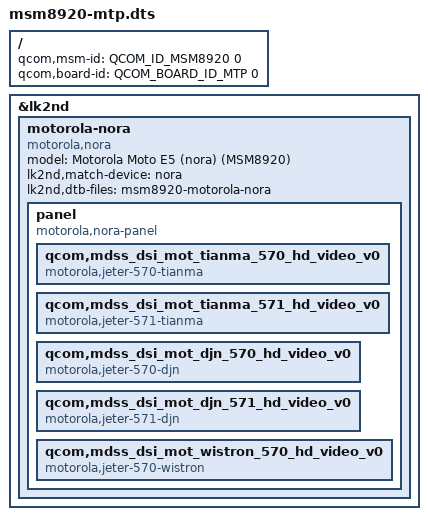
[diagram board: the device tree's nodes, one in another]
// SPDX-License-Identifier: BSD-3-Clause

/dts-v1/;

#include <skeleton64.dtsi>
#include <lk2nd.dtsi>

/ {
	qcom,msm-id = <QCOM_ID_MSM8920 0>;
	qcom,board-id = <QCOM_BOARD_ID_MTP 0>;
};

&lk2nd {
	motorola-nora {
		model = "Motorola Moto E5 (nora) (MSM8920)";
		compatible = "motorola,nora";
		lk2nd,match-device = "nora";

		lk2nd,dtb-files = "msm8920-motorola-nora";

		panel {
			compatible = "motorola,nora-panel", "lk2nd,panel";

			qcom,mdss_dsi_mot_tianma_570_hd_video_v0 {
				compatible = "motorola,jeter-570-tianma";
			};
			qcom,mdss_dsi_mot_tianma_571_hd_video_v0 {
				compatible = "motorola,jeter-571-tianma";
			};
			qcom,mdss_dsi_mot_djn_570_hd_video_v0 {
				compatible = "motorola,jeter-570-djn";
			};
			qcom,mdss_dsi_mot_djn_571_hd_video_v0 {
				compatible = "motorola,jeter-571-djn";
			};
			qcom,mdss_dsi_mot_wistron_570_hd_video_v0 {
				compatible = "motorola,jeter-570-wistron";
			};
		};
	};
};
